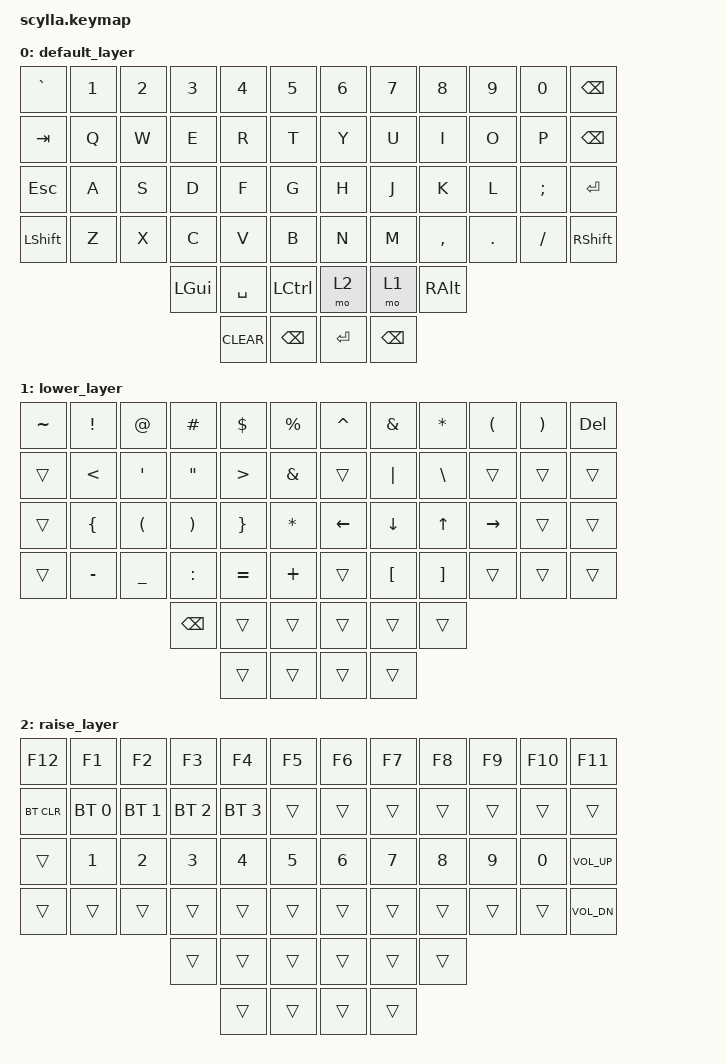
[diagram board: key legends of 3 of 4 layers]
#include <behaviors.dtsi>
#include <dt-bindings/zmk/bt.h>
#include <dt-bindings/zmk/keys.h>
#include <dt-bindings/zmk/outputs.h>

#define DEFAULT 0
#define LWR 1
#define RSE 2
#define ADJ 3

/ {
    combos {
        compatible = "zmk,combos";

        rgui-jkl {
            bindings = <&kp RIGHT_GUI>;
            key-positions = <31 32 33>;
        };

        lalt_sdf {
            bindings = <&kp LEFT_ALT>;
            key-positions = <28 27 26>;
        };
    };

    keymap {
        compatible = "zmk,keymap";

        default_layer {
            bindings = <
&kp GRAVE   &kp NUMBER_1  &kp N2  &kp N3        &kp N4     &kp N5              &kp N6     &kp N7         &kp N8         &kp N9   &kp N0    &kp BSPC
&kp TAB     &kp Q         &kp W   &kp E         &kp R      &kp T               &kp Y      &kp U          &kp I          &kp O    &kp P     &kp BACKSPACE
&kp ESCAPE  &kp A         &kp S   &kp D         &kp F      &kp G               &kp H      &kp J          &kp K          &kp L    &kp SEMI  &kp ENTER
&kp LSHIFT  &kp Z         &kp X   &kp C         &kp V      &kp B               &kp N      &kp M          &kp COMMA      &kp DOT  &kp FSLH  &kp RSHIFT
                                  &kp LEFT_GUI  &kp SPACE  &kp LEFT_CONTROL    &mo 2      &mo 1          &kp RIGHT_ALT
                                                &kp CLEAR  &kp BSPC            &kp ENTER  &kp BACKSPACE
            >;
        };

        lower_layer {
            bindings = <
&kp TILDE  &kp EXCL       &kp AT     &kp HASH       &kp DLLR          &kp PRCNT       &kp CARET  &kp AMPS          &kp ASTRK          &kp LPAR   &kp RPAR  &kp DEL
&trans     &kp LESS_THAN  &kp APOS   &kp DQT        &kp GREATER_THAN  &kp AMPS        &trans     &kp PIPE          &kp BACKSLASH      &trans     &trans    &trans
&trans     &kp LBRC       &kp LPAR   &kp RPAR       &kp RBRC          &kp ASTERISK    &kp LEFT   &kp DOWN          &kp UP_ARROW       &kp RIGHT  &trans    &trans
&trans     &kp MINUS      &kp UNDER  &kp COLON      &kp EQUAL         &kp PLUS        &trans     &kp LEFT_BRACKET  &kp RIGHT_BRACKET  &trans     &trans    &trans
                                     &kp BACKSPACE  &trans            &trans          &trans     &trans            &trans
                                                    &trans            &trans          &trans     &trans
            >;
        };

        raise_layer {
            bindings = <
&kp F12     &kp F1        &kp F2        &kp F3        &kp F4        &kp F5    &kp F6        &kp F7  &kp F8  &kp F9  &kp F10  &kp F11
&bt BT_CLR  &bt BT_SEL 0  &bt BT_SEL 1  &bt BT_SEL 2  &bt BT_SEL 3  &trans    &trans        &trans  &trans  &trans  &trans   &trans
&trans      &kp NUMBER_1  &kp NUMBER_2  &kp NUMBER_3  &kp NUMBER_4  &kp N5    &kp NUMBER_6  &kp N7  &kp N8  &kp N9  &kp N0   &kp C_VOL_UP
&trans      &trans        &trans        &trans        &trans        &trans    &trans        &trans  &trans  &trans  &trans   &kp C_VOL_DN
                                        &trans        &trans        &trans    &trans        &trans  &trans
                                                      &trans        &trans    &trans        &trans
            >;
        };

        adjust_layer {
            bindings = <
&out OUT_BLE  &bt BT_SEL 0  &bt BT_SEL 1  &bt BT_SEL 2  &bt BT_SEL 3  &bt BT_SEL 4    &none  &none  &none  &none  &none  &none
&out OUT_USB  &none         &none         &none         &trans        &none           &none  &none  &none  &none  &none  &none
&none         &none         &none         &none         &none         &none           &none  &none  &none  &none  &none  &bt BT_CLR
&none         &none         &none         &none         &bootloader   &none           &none  &none  &none  &none  &none  &none
                                          &none         &none         &none           &none  &none  &none
                                                        &none         &none           &none
            >;
        };
    };
};
